AUTOSAR XML (schema 4-2-2)
package /ASW_COM_Package
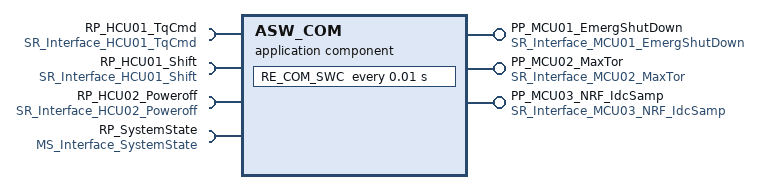
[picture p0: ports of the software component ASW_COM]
  application sw component type ASW_COM
    provide port PP_MCU01_EmergShutDown: provided-interface=SR_Interface_MCU01_EmergShutDown
    provide port PP_MCU02_MaxTor: provided-interface=SR_Interface_MCU02_MaxTor
    provide port PP_MCU03_NRF_IdcSamp: provided-interface=SR_Interface_MCU03_NRF_IdcSamp
    4 x require port:
      RP_HCU01_TqCmd: required-interface=SR_Interface_HCU01_TqCmd
      RP_HCU01_Shift: required-interface=SR_Interface_HCU01_Shift
      RP_HCU02_Poweroff: nonqueued-receiver-com-spec{data-element=HCU02_Poweroff, alive-timeout=0.3}, required-interface=SR_Interface_HCU02_Poweroff
      RP_SystemState: required-interface=MS_Interface_SystemState
    behavior IB_ASW_COM
      timing event TE_RE_COM_SWC_10ms: start-on-event=RE_COM_SWC, period=0.01
      runnable RE_COM_SWC
        data-receive-point-by-arguments:
          access REC_HCU01_TqCmd: accessed-variable=RP_HCU01_TqCmd.HCU01_TqCmd
          access REC_HCU01_Shift: accessed-variable=RP_HCU01_Shift.HCU01_Shift
          access REC_HCU02_Poweroff: accessed-variable=RP_HCU02_Poweroff.HCU02_Poweroff
        data-send-points:
          access SEND_MCU01_EmergShutDown: accessed-variable=PP_MCU01_EmergShutDown.MCU01_EmergShutDown
          access SEND_MCU02_MaxTor: accessed-variable=PP_MCU02_MaxTor.MCU02_MaxTor
          access SEND_MCU03_NRF_IdcSamp: accessed-variable=PP_MCU03_NRF_IdcSamp.MCU03_NRF_IdcSamp
        mode access point ACCESS_MODE_SLEEP: mode-group=RP_SystemState.SystemState
  swc implementation IMPL_ASW_COM: behavior=IB_ASW_COM
package /COM_Interface
  6 x sender receiver interface:
    SR_Interface_HCU01_TqCmd
      data HCU01_TqCmd: type=float32
    SR_Interface_HCU01_Shift
      data HCU01_Shift: type=uint8
    SR_Interface_HCU02_Poweroff
      data HCU02_Poweroff: type=boolean
    SR_Interface_MCU01_EmergShutDown
      data MCU01_EmergShutDown: type=boolean
    SR_Interface_MCU02_MaxTor
      data MCU02_MaxTor: type=float32
    SR_Interface_MCU03_NRF_IdcSamp
      data MCU03_NRF_IdcSamp: type=float32
  mode switch interface MS_Interface_SystemState
    mode group SystemState: type=MDG_SystemState
package /DataTypes
  app type boolean: category=BOOLEAN
  app type uint8: category=VALUE
  app type float32: category=VALUE
package /ModeDclrGroups
  mode declaration group MDG_SystemState: initial-mode=RUN
    mode SLEEP
    mode RUN
    mode WAKEUP
